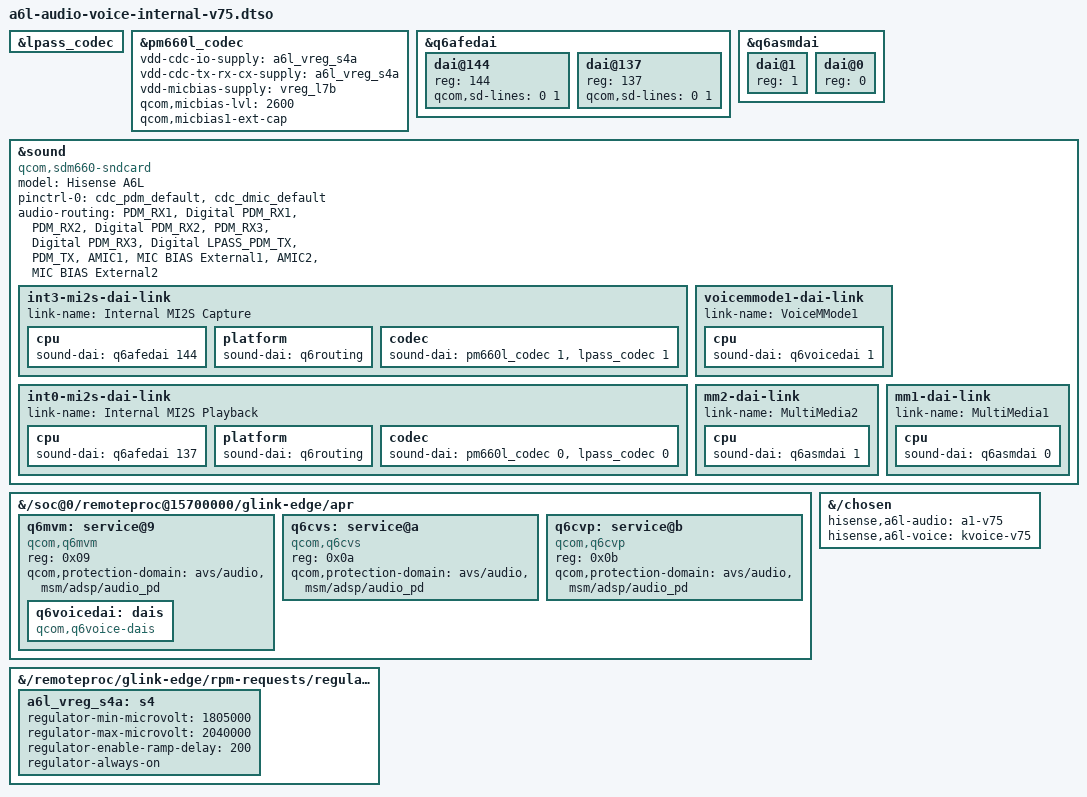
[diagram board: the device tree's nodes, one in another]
// SPDX-License-Identifier: GPL-2.0-only
// V75 CANDIDATE (kvoice agent, 24 Sep 2026), never booted. CALL AUDIO: q6voice (CVD: MVM/CVS/CVP APR services) + a
// "VoiceMMode1" front end (stock: VoiceMMode1 FE, INT0_MI2S_RX_Voice Mixer VoiceMMode1 = mainline LPI_MI2S_RX_0 Voice Mixer
// VoiceMMode1, VoiceMMode1_Tx Mixer INT3_MI2S_TX_MMode1 = mainline VoiceMMode1 Capture Mixer LPI_MI2S_TX_3).
// Kernel: sound/soc/qcom/qdsp6 q6voice series (sc7280-mainline PR #32, Stephan Gerhold / Richard Acayan) + a6l-q6voice-sdm660-v75.patch
// (LPI port routes, CVD version auto-detect). Modules: q6voice-common q6mvm q6cvs q6cvp q6voice q6voice-dai.
// fdtoverlay (and the kernel overlay code) PREPEND new child nodes: see docs/audio3-20260924.md; link order is asserted by
// tools/check-voice-dt-links.py <merged.dtb> (FEs MultiMedia1, MultiMedia2, VoiceMMode1 first, then the q6routing BEs).
// VARIANT: base WITHOUT sound links (use INSTEAD of a6l-audio-internal-v75.dtso). = a6l-audio-internal-v75.dtso + the q6voice services and a VoiceMMode1 FE
// written just before mm2 in this REVERSED list -> merged: MultiMedia1, MultiMedia2, VoiceMMode1, [Speaker], Int Playback, Int Capture.
// Correct with the stock and the patched q6asm-dai. ---- original audio3 header follows ----
// SPDX-License-Identifier: GPL-2.0-only
// V75 CANDIDATE (audio3 agent, 24 Sep 2026), never booted. Internal audio path only (headset, headset mic, main mic; the
// earpiece is wired too but broken on Pierre's unit). Same content as a6l-audio-internal.dtso ("a1") except the FIX below.
// For a base DTB WITHOUT sound links / q6asm-dais children (mainline sdm630.dtsi-based build). On the V71/V74 base.dtb,
// which already carries the a1 nodes in the wrong order, fdtoverlay cannot reorder anything: there the fix is the module
// patch a6l-q6asm-dai-xlate-v75.patch (q6asm-dai.ko resolves <&q6asmdai N> by reg), which is also correct for this file.
//
// ROOT CAUSE of the 23 Sep "inverted DPCM" (audio2 diag r180): fdtoverlay PREPENDS new child nodes, so a1's
// "dai@0 { }; dai@1 { };" under &q6asmdai ended up as dai@1, dai@0 in the merged DTB. q6asm-dai.c has no of_xlate_dai_name,
// so snd_soc_get_dlc() maps <&q6asmdai 0> to the FIRST child = MultiMedia2. Link "MultiMedia1" (pcmC0D0) therefore used the
// MultiMedia2 DAI and vice versa: with "LPI_MI2S_RX_0 Audio Mixer MultiMedia1" (MM_DL1) and "MultiMedia2 Mixer
// LPI_MI2S_TX_3" (MM_UL2) on, only pcmC0D1p and pcmC0D0c had a back end -> exactly the observed open() pattern (EINVAL =
// dpcm_fe_dai_open "no backend DAIs"). Nothing was wrong with the DPCM direction, q6routing or the link flags.
// FIX: children below are written in REVERSE order (dai@1 first) so that the merged DTB lists dai@0, dai@1 (index == reg).
// The dai-links stay reversed on purpose too (merged order must be MultiMedia1, MultiMedia2, then the q6routing BEs).
// Check: tools/check-audio-dt-links.py <merged.dtb> must print "A6L_DT_CHECK PASS rule=both".
/dts-v1/;
/plugin/;
&lpass_codec { status = "okay"; };
&pm660l_codec {
    vdd-cdc-io-supply = <&a6l_vreg_s4a>;
    vdd-cdc-tx-rx-cx-supply = <&a6l_vreg_s4a>;
    vdd-micbias-supply = <&vreg_l7b>;
    qcom,micbias-lvl = <2600>;
    qcom,micbias1-ext-cap;
    status = "okay";
};
&q6afedai {
    #address-cells = <1>;
    #size-cells = <0>;
    dai@144 { reg = <144>; qcom,sd-lines = <0 1>; };   /* LPI_MI2S_TX_3 (q6afe-dai resolves by port id: order irrelevant) */
    dai@137 { reg = <137>; qcom,sd-lines = <0 1>; };   /* LPI_MI2S_RX_0 */
};
&q6asmdai {
    #address-cells = <1>;
    #size-cells = <0>;
    dai@1 { reg = <1>; };   /* REVERSED ON PURPOSE -> merged: dai@0 (MultiMedia1) first, dai@1 (MultiMedia2) second */
    dai@0 { reg = <0>; };
};
&sound {
    compatible = "qcom,sdm660-sndcard";
    model = "Hisense A6L";
    pinctrl-names = "default";
    pinctrl-0 = <&cdc_pdm_default>, <&cdc_dmic_default>;
    audio-routing = "PDM_RX1", "Digital PDM_RX1", "PDM_RX2", "Digital PDM_RX2", "PDM_RX3", "Digital PDM_RX3",
                    "Digital LPASS_PDM_TX", "PDM_TX", "AMIC1", "MIC BIAS External1", "AMIC2", "MIC BIAS External2";
    // REVERSED ON PURPOSE: merged order = MultiMedia1, MultiMedia2, Internal MI2S Playback, Internal MI2S Capture
    int3-mi2s-dai-link {
        link-name = "Internal MI2S Capture";
        cpu { sound-dai = <&q6afedai 144>; };
        platform { sound-dai = <&q6routing>; };
        codec { sound-dai = <&pm660l_codec 1>, <&lpass_codec 1>; };
    };
    int0-mi2s-dai-link {
        link-name = "Internal MI2S Playback";
        cpu { sound-dai = <&q6afedai 137>; };
        platform { sound-dai = <&q6routing>; };
        codec { sound-dai = <&pm660l_codec 0>, <&lpass_codec 0>; };
    };
    voicemmode1-dai-link { link-name = "VoiceMMode1"; cpu { sound-dai = <&q6voicedai 1>; }; };  /* kvoice: merged -> after MultiMedia2 */
    mm2-dai-link { link-name = "MultiMedia2"; cpu { sound-dai = <&q6asmdai 1>; }; };
    mm1-dai-link { link-name = "MultiMedia1"; cpu { sound-dai = <&q6asmdai 0>; }; };
};
/ {
    /* CVD services on the ADSP APR bus (same PD as q6afe/q6asm/q6adm in sdm630.dtsi). APR_SVC_ADSP_MVM/CVS/CVP = 9/0xa/0xb */
    fragment@80 {
        target-path = "/soc@0/remoteproc@15700000/glink-edge/apr";
        __overlay__ {
            #address-cells = <1>;
            #size-cells = <0>;
            q6mvm: service@9 {
                compatible = "qcom,q6mvm";
                reg = <0x09>;
                qcom,protection-domain = "avs/audio", "msm/adsp/audio_pd";
                q6voicedai: dais {
                    compatible = "qcom,q6voice-dais";
                    #sound-dai-cells = <1>;     /* <&q6voicedai 1> = VOICEMMODE1 (index == id: CS_VOICE 0, VOICEMMODE1 1) */
                    /* no qcom,cvd-v2.3 / qcom,cvd-v2.2: q6voice asks MVM (VSS_IVERSION_CMD_GET); q6voice.cvd_mode= overrides */
                };
            };
            q6cvs: service@a {
                compatible = "qcom,q6cvs";
                reg = <0x0a>;
                qcom,protection-domain = "avs/audio", "msm/adsp/audio_pd";
            };
            q6cvp: service@b {
                compatible = "qcom,q6cvp";
                reg = <0x0b>;
                qcom,protection-domain = "avs/audio", "msm/adsp/audio_pd";
            };
        };
    };
    fragment@90 {
        target-path = "/remoteproc/glink-edge/rpm-requests/regulators-1";
        __overlay__ { a6l_vreg_s4a: s4 { regulator-min-microvolt = <1805000>; regulator-max-microvolt = <2040000>; regulator-enable-ramp-delay = <200>; regulator-always-on; }; };
    };
    fragment@91 { target-path = "/chosen"; __overlay__ { hisense,a6l-audio = "a1-v75"; hisense,a6l-voice = "kvoice-v75"; }; };
};
